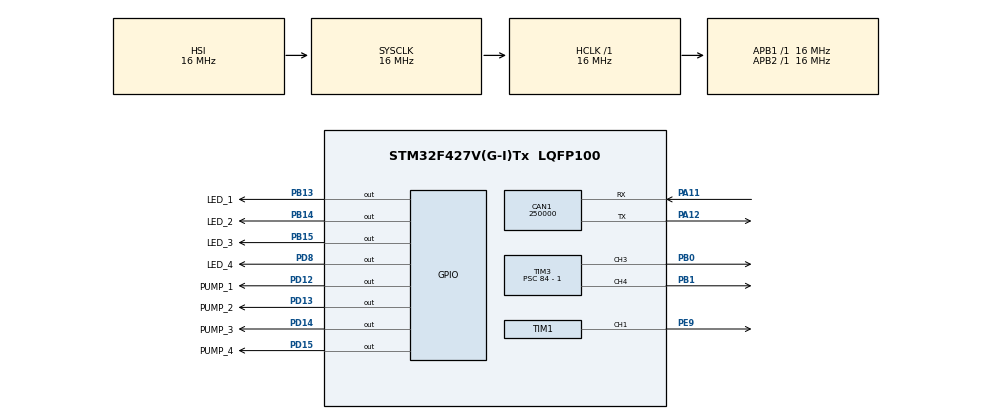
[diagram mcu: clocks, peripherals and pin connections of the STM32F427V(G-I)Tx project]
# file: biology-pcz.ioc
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CAN1.BS1=CAN_BS1_2TQ
CAN1.CalculateBaudRate=250000
CAN1.CalculateTimeBit=4000
CAN1.CalculateTimeQuantum=1000.0
CAN1.Mode=CAN_MODE_LOOPBACK
Mcu.Family=STM32F4
Mcu.Name=STM32F427V(G-I)Tx
Mcu.Package=LQFP100
NVIC.PriorityGroup=NVIC_PRIORITYGROUP_4
PA11.Mode=CAN_Activate
PA11.Signal=CAN1_RX
PA12.Mode=CAN_Activate
PA12.Signal=CAN1_TX
PA13.Mode=Serial_Wire
PA13.Signal=SYS_JTMS-SWDIO
PA14.Mode=Serial_Wire
PA14.Signal=SYS_JTCK-SWCLK
PB0.Signal=S_TIM3_CH3
PB1.Signal=S_TIM3_CH4
PB13.GPIO_Label=LED_1
PB13.Signal=GPIO_Output
PB14.GPIO_Label=LED_2
PB14.Signal=GPIO_Output
PB15.GPIO_Label=LED_3
PB15.Signal=GPIO_Output
PD12.GPIO_Label=PUMP_1
PD12.Signal=GPIO_Output
PD13.GPIO_Label=PUMP_2
PD13.Signal=GPIO_Output
PD14.GPIO_Label=PUMP_3
PD14.Signal=GPIO_Output
PD15.GPIO_Label=PUMP_4
PD15.Signal=GPIO_Output
PD8.GPIO_Label=LED_4
PD8.Signal=GPIO_Output
PE9.Signal=S_TIM1_CH1
PH0/OSC_IN.Mode=HSE-External-Oscillator
PH0/OSC_IN.Signal=RCC_OSC_IN
PH1/OSC_OUT.Mode=HSE-External-Oscillator
PH1/OSC_OUT.Signal=RCC_OSC_OUT
ProjectManager.HeapSize=0x200
ProjectManager.StackSize=0x400
ProjectManager.TargetToolchain=STM32CubeIDE
RCC.AHBFreq_Value=16000000
RCC.APB1Freq_Value=16000000
RCC.APB2Freq_Value=16000000
RCC.CortexFreq_Value=16000000
RCC.HSE_VALUE=25000000
RCC.HSI_VALUE=16000000
RCC.LSE_VALUE=32768
RCC.SYSCLKFreq_VALUE=16000000
RCC.VCOOutputFreq_Value=192000000
SH.S_TIM1_CH1.0=TIM1_CH1,PWM Generation1 CH1
SH.S_TIM3_CH3.0=TIM3_CH3,PWM Generation3 CH3
SH.S_TIM3_CH4.0=TIM3_CH4,PWM Generation4 CH4
TIM1.Channel-PWM\ Generation1\ CH1=TIM_CHANNEL_1
TIM1.Period=9999
TIM1.Prescaler=15
TIM3.Channel-PWM\ Generation3\ CH3=TIM_CHANNEL_3
TIM3.Channel-PWM\ Generation4\ CH4=TIM_CHANNEL_4
TIM3.Period=20000 - 1
TIM3.Prescaler=84 - 1
VP_TIM1_VS_ClockSourceINT.Mode=Internal
VP_TIM3_VS_ClockSourceINT.Mode=Internal
board=custom

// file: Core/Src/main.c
/* USER CODE BEGIN Header */
/**
  ******************************************************************************
  * @file           : main.c
  * @brief          : Main program body
  ******************************************************************************
  * @attention
  *
  * Copyright (c) 2025 STMicroelectronics.
  * All rights reserved.
  *
  * This software is licensed under terms that can be found in the LICENSE file
  * in the root directory of this software component.
  * If no LICENSE file comes with this software, it is provided AS-IS.
  *
  ******************************************************************************
  */
/* USER CODE END Header */
#include "main.h"
#include "can.h"
#include "tim.h"
#include "gpio.h"

void SystemClock_Config(void);

int main(void)
{

  /* MCU Configuration--------------------------------------------------------*/

  /* Reset of all peripherals, Initializes the Flash interface and the Systick. */
  HAL_Init();

  /* Configure the system clock */
  SystemClock_Config();

  /* Initialize all configured peripherals */
  MX_GPIO_Init();
  MX_CAN1_Init();
  MX_TIM1_Init();
  MX_TIM3_Init();
  /* USER CODE BEGIN 2 */

  HAL_TIM_PWM_Start(&htim1, TIM_CHANNEL_1);
  HAL_TIM_PWM_Start(&htim3, TIM_CHANNEL_3);
  HAL_TIM_PWM_Start(&htim3, TIM_CHANNEL_4);

  Test_Init();

  HAL_TIM_PWM_Stop(&htim1, TIM_CHANNEL_1);
  HAL_TIM_PWM_Stop(&htim3, TIM_CHANNEL_3);
  HAL_TIM_PWM_Stop(&htim3, TIM_CHANNEL_4);

  /* USER CODE END 2 */

  /* Infinite loop */
  while (1)
  {

  }
}

void SystemClock_Config(void)
{
  RCC_OscInitTypeDef RCC_OscInitStruct = {0};
  RCC_ClkInitTypeDef RCC_ClkInitStruct = {0};

  /** Configure the main internal regulator output voltage
  */
  __HAL_RCC_PWR_CLK_ENABLE();
  __HAL_PWR_VOLTAGESCALING_CONFIG(PWR_REGULATOR_VOLTAGE_SCALE3);

  /** Initializes the RCC Oscillators according to the specified parameters
  * in the RCC_OscInitTypeDef structure.
  */
  RCC_OscInitStruct.OscillatorType = RCC_OSCILLATORTYPE_HSI;
  RCC_OscInitStruct.HSIState = RCC_HSI_ON;
  RCC_OscInitStruct.HSICalibrationValue = RCC_HSICALIBRATION_DEFAULT;
  RCC_OscInitStruct.PLL.PLLState = RCC_PLL_NONE;
  if (HAL_RCC_OscConfig(&RCC_OscInitStruct) != HAL_OK)
  {
    Error_Handler();
  }

  /** Initializes the CPU, AHB and APB buses clocks
  */
  RCC_ClkInitStruct.ClockType = RCC_CLOCKTYPE_HCLK|RCC_CLOCKTYPE_SYSCLK
                              |RCC_CLOCKTYPE_PCLK1|RCC_CLOCKTYPE_PCLK2;
  RCC_ClkInitStruct.SYSCLKSource = RCC_SYSCLKSOURCE_HSI;
  RCC_ClkInitStruct.AHBCLKDivider = RCC_SYSCLK_DIV1;
  RCC_ClkInitStruct.APB1CLKDivider = RCC_HCLK_DIV1;
  RCC_ClkInitStruct.APB2CLKDivider = RCC_HCLK_DIV1;

  if (HAL_RCC_ClockConfig(&RCC_ClkInitStruct, FLASH_LATENCY_0) != HAL_OK)
  {
    Error_Handler();
  }
}

void Error_Handler(void)
{
  __disable_irq();
  while (1)
  {
  }
}
